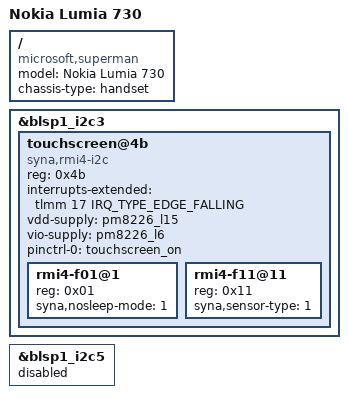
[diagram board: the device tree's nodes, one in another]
// SPDX-License-Identifier: BSD-3-Clause
/*
 * Copyright (c) 2022, Jack Matthews <jm5112356@gmail.com>
 * Copyright (c) 2022, Ivaylo Ivanov <ivo.ivanov.ivanov1@gmail.com>
 * Copyright (c) 2022, Dominik Kobinski <dominikkobinski314@gmail.com>
 * Copyright (c) 2022, Rayyan Ansari <rayyan@ansari.sh>
 */

/dts-v1/;

#include "qcom-msm8226-microsoft-common.dtsi"

/ {
	model = "Nokia Lumia 730";
	compatible = "microsoft,superman", "qcom,msm8226";
	chassis-type = "handset";
};

&blsp1_i2c3 {
	status = "okay";

	touchscreen@4b {
		compatible = "syna,rmi4-i2c";
		reg = <0x4b>;

		interrupts-extended = <&tlmm 17 IRQ_TYPE_EDGE_FALLING>;
		vdd-supply = <&pm8226_l15>;
		vio-supply = <&pm8226_l6>;

		pinctrl-names = "default";
		pinctrl-0 = <&touchscreen_on>;

		#address-cells = <1>;
		#size-cells = <0>;

		rmi4-f01@1 {
			reg = <0x01>;
			syna,nosleep-mode = <1>;
		};

		rmi4-f11@11 {
			reg = <0x11>;
			syna,sensor-type = <1>;
		};
	};
};

&blsp1_i2c5 {
	status = "disabled";
	/delete-node/ touchscreen@4b;
};
